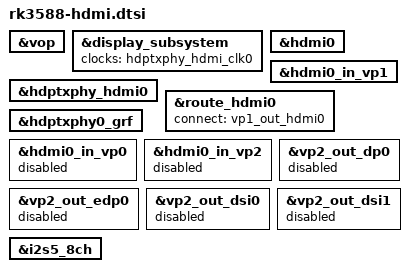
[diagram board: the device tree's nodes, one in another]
// SPDX-License-Identifier: (GPL-2.0+ OR MIT)
/*
 * Copyright (c) 2021 Rockchip Electronics Co., Ltd.
 *
 */

&vop {
	status = "okay";
};
 
&display_subsystem {
	clocks = <&hdptxphy_hdmi_clk0>;
	clock-names = "hdmi0_phy_pll";
	status = "okay";
};

&hdmi0 {
	status = "okay";   //"disabled"; //		 +1
};

&hdmi0_in_vp1 {
	status = "okay";
};

&hdptxphy_hdmi0 {
	status = "okay";
};

&route_hdmi0 {
	status = "okay";
	connect = <&vp1_out_hdmi0>;              //+3
};

&hdptxphy0_grf {
	status = "okay";
};


&hdmi0_in_vp0 {
	status = "disabled";
};


&hdmi0_in_vp2 {
	status = "disabled";
};

&vp2_out_dp0 {
	status = "disabled";
};

&vp2_out_edp0 {
	status = "disabled";
};

&vp2_out_dsi0 {
	status = "disabled";
};

&vp2_out_dsi1 {
	status = "disabled";
};

&hdptxphy_hdmi0 {
	status = "okay";
};

&route_hdmi0{
	status = "okay";
};

&i2s5_8ch {
	status = "okay";
};




